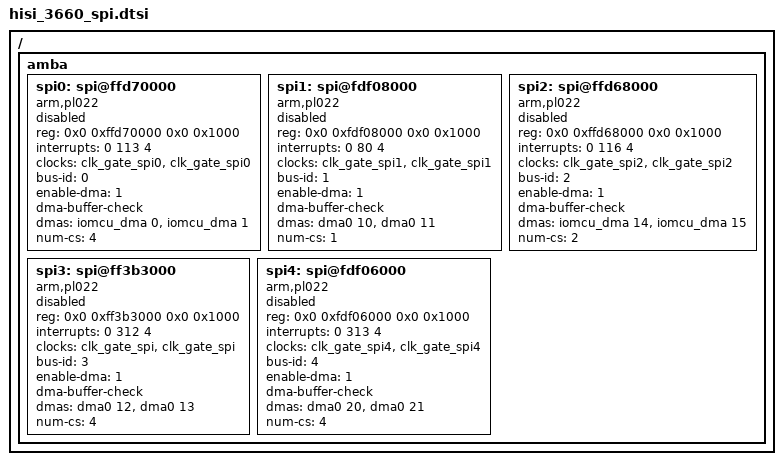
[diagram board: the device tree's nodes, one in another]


/{
	amba{
		spi0: spi@ffd70000 {
				compatible = "arm,pl022", "arm,primecell";
				status = "disabled";
				reg = <0x0 0xffd70000 0x0 0x1000>;
				interrupts = <0 113 4>;
				clocks = <&clk_gate_spi0 &clk_gate_spi0>;
				clock-names = "clk_spi0", "apb_pclk";
				bus-id = <0>;
				enable-dma = <1>;
				dma-buffer-check;
				dmas =  <&iomcu_dma 0
				         &iomcu_dma 1>;
				dma-names = "rx", "tx";
				num-cs = <4>;
				//cs-gpios = <&gpio6 2 0>, <&gpio6 3 0>, <&gpio6 4 0>, <&gpio6 5 0>;
		};

		spi1: spi@fdf08000 {
            compatible = "arm,pl022", "arm,primecell";
			status = "disabled";
			reg = <0x0 0xfdf08000 0x0 0x1000>;
			interrupts = <0 80 4>;
			clocks = <&clk_gate_spi1 &clk_gate_spi1>;
			clock-names = "clk_spi1", "apb_pclk";
			bus-id = <1>;
			enable-dma = <1>;
			dma-buffer-check;
			dmas =  <&dma0 10
				&dma0 11>;
			dma-names = "rx", "tx";
			num-cs = <1>;
		};

		spi2: spi@ffd68000 {
            compatible = "arm,pl022", "arm,primecell";
			status = "disabled";
			reg = <0x0 0xffd68000 0x0 0x1000>;
			interrupts = <0 116 4>;
			clocks = <&clk_gate_spi2 &clk_gate_spi2>;
			clock-names = "clk_spi2", "apb_pclk";
			bus-id = <2>;
			enable-dma = <1>;
			dma-buffer-check;
			dmas =  <&iomcu_dma 14
				&iomcu_dma 15>;
			dma-names = "rx", "tx";
			num-cs = <2>;
		};

		spi3: spi@ff3b3000 {
            compatible = "arm,pl022", "arm,primecell";
			status = "disabled";
			reg = <0x0 0xff3b3000 0x0 0x1000>;
			interrupts = <0 312 4>;
			/*TO DO:fix me for clk_gate_spi3*/
			clocks = <&clk_gate_spi &clk_gate_spi>;
			clock-names = "clk_spi3", "apb_pclk";
			bus-id = <3>;
			enable-dma = <1>;
			dma-buffer-check;
			dmas =  <&dma0 12
				&dma0 13>;
			dma-names = "rx", "tx";
			num-cs = <4>;
		};

		spi4: spi@fdf06000 {
            compatible = "arm,pl022", "arm,primecell";
			status = "disabled";
			reg = <0x0 0xfdf06000 0x0 0x1000>;
			interrupts = <0 313 4>;
			/*TO DO:fix me for clk_gate_spi4*/
			clocks = <&clk_gate_spi4 &clk_gate_spi4>;
			clock-names = "clk_spi4", "apb_pclk";
			bus-id = <4>;
			enable-dma = <1>;
			dma-buffer-check;
			dmas =  <&dma0 20
				&dma0 21>;
			dma-names = "rx", "tx";
			num-cs = <4>;
		};
	};
};
